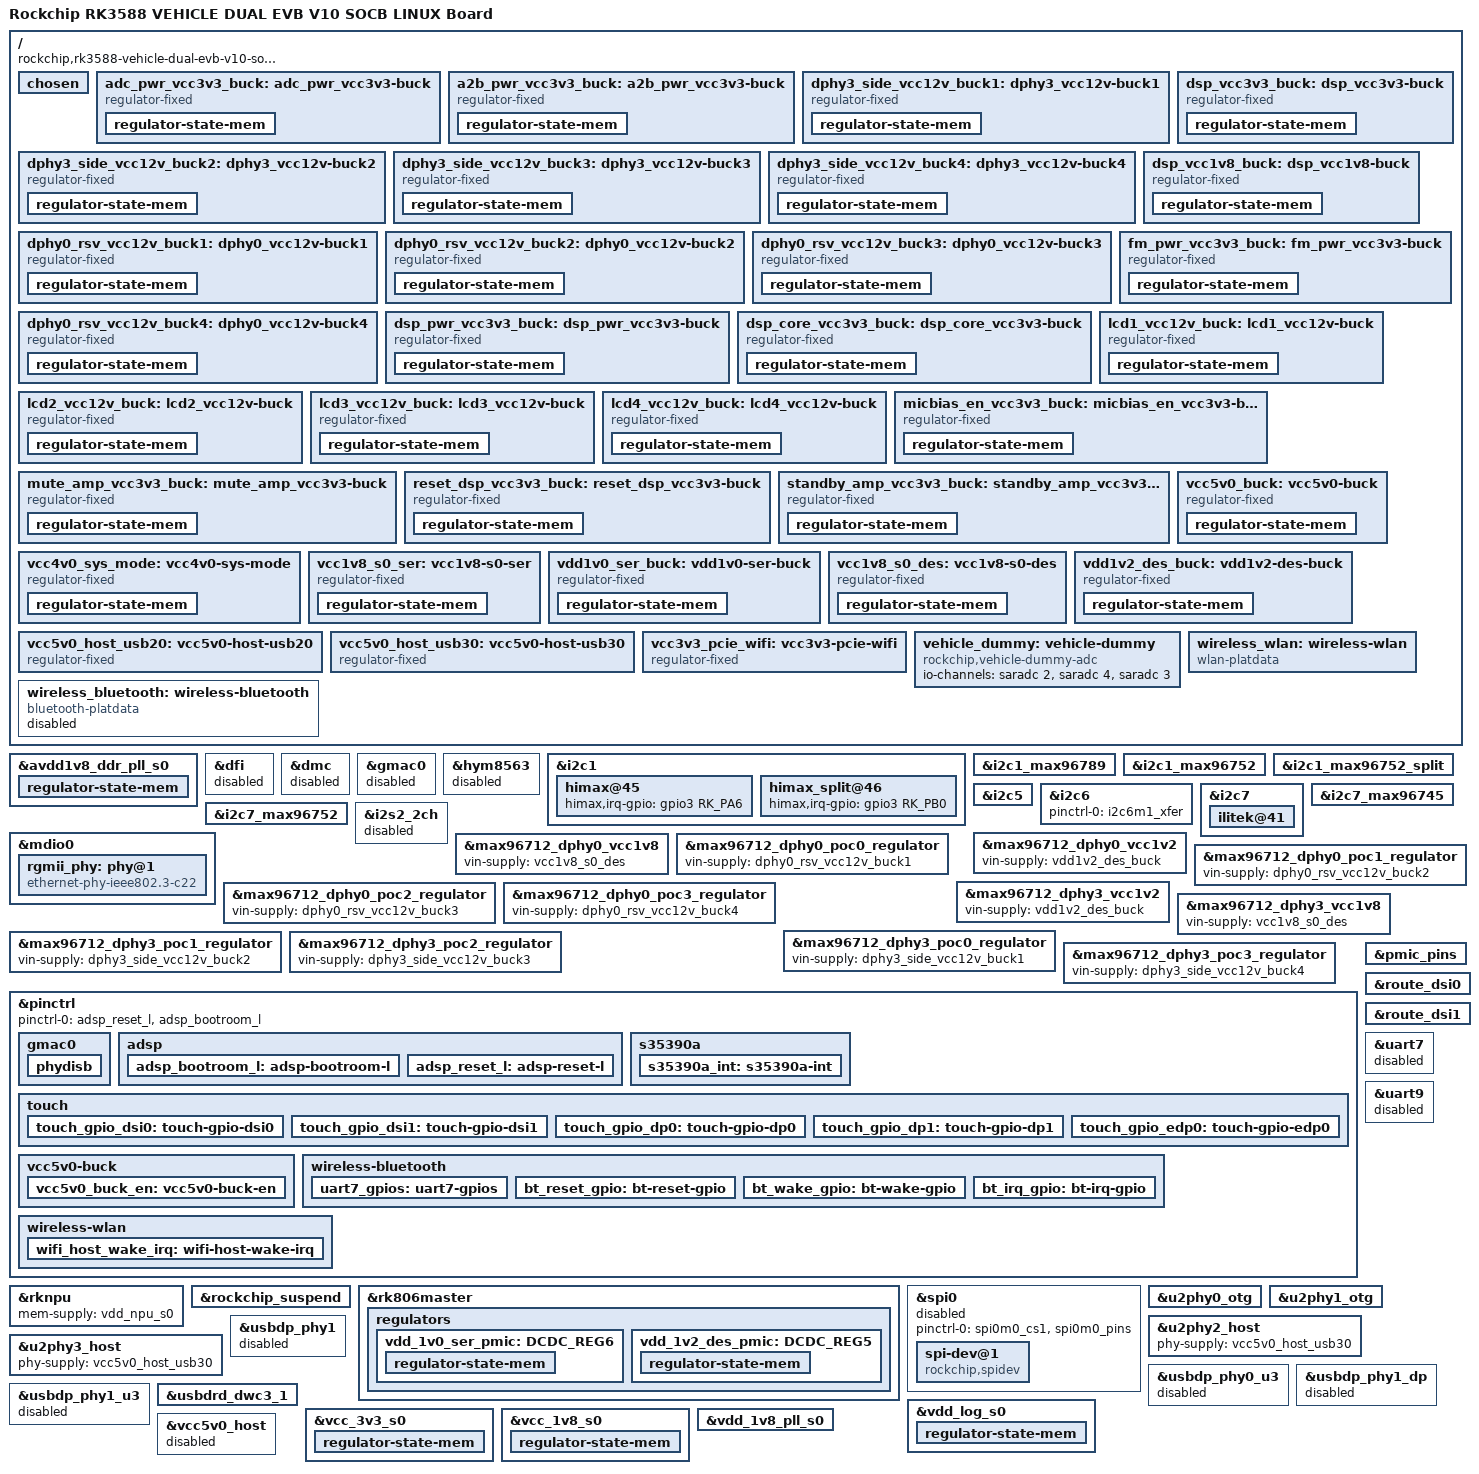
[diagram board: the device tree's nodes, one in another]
// SPDX-License-Identifier: (GPL-2.0+ OR MIT)
/*
 * Copyright (c) 2023 Rockchip Electronics Co., Ltd.
 *
 */

/dts-v1/;

#include "rk3588-vehicle-dual-evb-v10-socb.dtsi"

#include "rk3588-vehicle-dual-evb-v10-socb-mcu-io-expander.dtsi"
#include "rk3588-vehicle-dual-evb-v10-socb-maxim-max96712-dphy0-ox03j10.dtsi"
#include "rk3588-vehicle-dual-evb-v10-socb-maxim-max96712-dphy3-ox03j10.dtsi"
#include "rk3588-vehicle-dual-evb-v10-socb-serdes-mfd-display-maxim.dtsi"
#include "rk3588-linux.dtsi"

/ {
	model = "Rockchip RK3588 VEHICLE DUAL EVB V10 SOCB LINUX Board";
	compatible = "rockchip,rk3588-vehicle-dual-evb-v10-socb-linux", "rockchip,rk3588";

	chosen: chosen {
		bootargs = "earlycon=uart8250,mmio32,0xfeb50000 console=ttyFIQ0 irqchip.gicv3_pseudo_nmi=0 root=PARTUUID=614e0000-0000 rw rootwait rcupdate.rcu_expedited=1 rcu_nocbs=all";
	};

	adc_pwr_vcc3v3_buck: adc_pwr_vcc3v3-buck {
		compatible = "regulator-fixed";
		regulator-name = "adc_pwr_vcc3v3_buck";
		regulator-boot-on;
		regulator-always-on;
		regulator-min-microvolt = <3300000>;
		regulator-max-microvolt = <3300000>;
		enable-active-high;
		gpio = <&gpio_mcu_rockchip_socb MCU_ADC_PWDN_L GPIO_ACTIVE_LOW>;
		vin-supply = <&vcc_3v3_s3>;
		regulator-state-mem {
			regulator-off-in-suspend;
			regulator-suspend-microvolt = <3300000>;
		};
	};

	a2b_pwr_vcc3v3_buck: a2b_pwr_vcc3v3-buck {
		compatible = "regulator-fixed";
		regulator-name = "a2b_pwr_vcc3v3_buck";
		regulator-boot-on;
		regulator-always-on;
		regulator-min-microvolt = <3300000>;
		regulator-max-microvolt = <3300000>;
		enable-active-high;
		gpio = <&gpio_mcu_rockchip_socb MCU_A2B_PWR_EN_H GPIO_ACTIVE_HIGH>;
		vin-supply = <&vcc_3v3_s3>;
		regulator-state-mem {
			regulator-off-in-suspend;
			regulator-suspend-microvolt = <3300000>;
		};
	};

	dphy3_side_vcc12v_buck1: dphy3_vcc12v-buck1 {
		compatible = "regulator-fixed";
		regulator-name = "dphy3_side_vcc12v_buck1";
		regulator-boot-on;
		regulator-min-microvolt = <12000000>;
		regulator-max-microvolt = <12000000>;
		enable-active-high;
		gpio = <&gpio_mcu_rockchip_socb VCC12V_SIDE1 GPIO_ACTIVE_HIGH>;
		startup-delay-us = <2000>;
		off-on-delay-us = <16000>;
		vin-supply = <&vcc12v_dcin>;
		regulator-state-mem {
			regulator-off-in-suspend;
			regulator-suspend-microvolt = <12000000>;
		};
	};

	dphy3_side_vcc12v_buck2: dphy3_vcc12v-buck2 {
		compatible = "regulator-fixed";
		regulator-name = "dphy3_side_vcc12v_buck2";
		regulator-boot-on;
		regulator-min-microvolt = <12000000>;
		regulator-max-microvolt = <12000000>;
		enable-active-high;
		gpio = <&gpio_mcu_rockchip_socb VCC12V_SIDE2 GPIO_ACTIVE_HIGH>;
		startup-delay-us = <2000>;
		off-on-delay-us = <16000>;
		vin-supply = <&vcc12v_dcin>;
		regulator-state-mem {
			regulator-off-in-suspend;
			regulator-suspend-microvolt = <12000000>;
		};
	};

	dphy3_side_vcc12v_buck3: dphy3_vcc12v-buck3 {
		compatible = "regulator-fixed";
		regulator-name = "dphy3_side_vcc12v_buck3";
		regulator-boot-on;
		regulator-min-microvolt = <12000000>;
		regulator-max-microvolt = <12000000>;
		enable-active-high;
		gpio = <&gpio_mcu_rockchip_socb VCC12V_SIDE3 GPIO_ACTIVE_HIGH>;
		startup-delay-us = <2000>;
		off-on-delay-us = <16000>;
		vin-supply = <&vcc12v_dcin>;
		regulator-state-mem {
			regulator-off-in-suspend;
			regulator-suspend-microvolt = <12000000>;
		};
	};

	dphy3_side_vcc12v_buck4: dphy3_vcc12v-buck4 {
		compatible = "regulator-fixed";
		regulator-name = "dphy3_side_vcc12v_buck4";
		regulator-boot-on;
		regulator-min-microvolt = <12000000>;
		regulator-max-microvolt = <12000000>;
		enable-active-high;
		gpio = <&gpio_mcu_rockchip_socb VCC12V_SIDE4 GPIO_ACTIVE_HIGH>;
		startup-delay-us = <2000>;
		off-on-delay-us = <16000>;
		vin-supply = <&vcc12v_dcin>;
		regulator-state-mem {
			regulator-off-in-suspend;
			regulator-suspend-microvolt = <12000000>;
		};
	};

	dphy0_rsv_vcc12v_buck1: dphy0_vcc12v-buck1 {
		compatible = "regulator-fixed";
		regulator-name = "dphy0_rsv_vcc12v_buck1";
		regulator-boot-on;
		regulator-min-microvolt = <12000000>;
		regulator-max-microvolt = <12000000>;
		enable-active-high;
		gpio = <&gpio_mcu_rockchip_socb VCC12V_CAM_RSV1 GPIO_ACTIVE_HIGH>;
		startup-delay-us = <2000>;
		off-on-delay-us = <16000>;
		vin-supply = <&vcc12v_dcin>;
		regulator-state-mem {
			regulator-off-in-suspend;
			regulator-suspend-microvolt = <12000000>;
		};
	};

	dphy0_rsv_vcc12v_buck2: dphy0_vcc12v-buck2 {
		compatible = "regulator-fixed";
		regulator-name = "dphy0_rsv_vcc12v_buck2";
		regulator-boot-on;
		regulator-min-microvolt = <12000000>;
		regulator-max-microvolt = <12000000>;
		enable-active-high;
		gpio = <&gpio_mcu_rockchip_socb VCC12V_CAM_RSV2 GPIO_ACTIVE_HIGH>;
		startup-delay-us = <2000>;
		off-on-delay-us = <16000>;
		vin-supply = <&vcc12v_dcin>;
		regulator-state-mem {
			regulator-off-in-suspend;
			regulator-suspend-microvolt = <12000000>;
		};
	};

	dphy0_rsv_vcc12v_buck3: dphy0_vcc12v-buck3 {
		compatible = "regulator-fixed";
		regulator-name = "dphy0_rsv_vcc12v_buck3";
		regulator-boot-on;
		regulator-min-microvolt = <12000000>;
		regulator-max-microvolt = <12000000>;
		enable-active-high;
		gpio = <&gpio_mcu_rockchip_socb VCC12V_CAM_RSV3 GPIO_ACTIVE_HIGH>;
		startup-delay-us = <2000>;
		off-on-delay-us = <16000>;
		vin-supply = <&vcc12v_dcin>;
		regulator-state-mem {
			regulator-off-in-suspend;
			regulator-suspend-microvolt = <12000000>;
		};
	};

	dphy0_rsv_vcc12v_buck4: dphy0_vcc12v-buck4 {
		compatible = "regulator-fixed";
		regulator-name = "dphy0_rsv_vcc12v_buck4";
		regulator-boot-on;
		regulator-min-microvolt = <12000000>;
		regulator-max-microvolt = <12000000>;
		enable-active-high;
		gpio = <&gpio_mcu_rockchip_socb VCC12V_CAM_RSV4 GPIO_ACTIVE_HIGH>;
		startup-delay-us = <2000>;
		off-on-delay-us = <16000>;
		vin-supply = <&vcc12v_dcin>;
		regulator-state-mem {
			regulator-off-in-suspend;
			regulator-suspend-microvolt = <12000000>;
		};
	};

	dsp_vcc3v3_buck: dsp_vcc3v3-buck {
		compatible = "regulator-fixed";
		regulator-name = "dsp_vcc3v3_buck";
		regulator-boot-on;
		regulator-always-on;
		regulator-min-microvolt = <3300000>;
		regulator-max-microvolt = <3300000>;
		enable-active-high;
		gpio = <&gpio_mcu_rockchip_socb MCU_DSP_3V3_EN_H GPIO_ACTIVE_HIGH>;
		vin-supply = <&vcc_3v3_s3>;
		regulator-state-mem {
			regulator-off-in-suspend;
			regulator-suspend-microvolt = <3300000>;
		};
	};

	dsp_vcc1v8_buck: dsp_vcc1v8-buck {
		compatible = "regulator-fixed";
		regulator-name = "dsp_vcc1v8_buck";
		regulator-boot-on;
		regulator-always-on;
		regulator-min-microvolt = <1800000>;
		regulator-max-microvolt = <1800000>;
		enable-active-high;
		gpio = <&gpio_mcu_rockchip_socb MCU_DSP_1V8_EN_H GPIO_ACTIVE_HIGH>;
		vin-supply = <&vcc_1v8_s0>;
		regulator-state-mem {
			regulator-off-in-suspend;
			regulator-suspend-microvolt = <1800000>;
		};
	};

	dsp_pwr_vcc3v3_buck: dsp_pwr_vcc3v3-buck {
		compatible = "regulator-fixed";
		regulator-name = "dsp_pwr_vcc3v3_buck";
		regulator-boot-on;
		regulator-always-on;
		regulator-min-microvolt = <3300000>;
		regulator-max-microvolt = <3300000>;
		enable-active-high;
		gpio = <&gpio_mcu_rockchip_socb MCU_DSP0_PWREN_H GPIO_ACTIVE_HIGH>;
		vin-supply = <&vcc_3v3_s3>;
		regulator-state-mem {
			regulator-off-in-suspend;
			regulator-suspend-microvolt = <3300000>;
		};
	};

	dsp_core_vcc3v3_buck: dsp_core_vcc3v3-buck {
		compatible = "regulator-fixed";
		regulator-name = "dsp_core_vcc3v3_buck";
		regulator-boot-on;
		regulator-always-on;
		regulator-min-microvolt = <3300000>;
		regulator-max-microvolt = <3300000>;
		enable-active-high;
		gpio = <&gpio_mcu_rockchip_socb MCU_DSPCORE_PWREN_H GPIO_ACTIVE_HIGH>;
		vin-supply = <&vcc_3v3_s3>;
		regulator-state-mem {
			regulator-off-in-suspend;
			regulator-suspend-microvolt = <3300000>;
		};
	};

	fm_pwr_vcc3v3_buck: fm_pwr_vcc3v3-buck {
		compatible = "regulator-fixed";
		regulator-name = "fm_pwr_vcc3v3_buck";
		regulator-boot-on;
		regulator-always-on;
		regulator-min-microvolt = <3300000>;
		regulator-max-microvolt = <3300000>;
		enable-active-high;
		gpio = <&gpio_mcu_rockchip_socb MCU_FM_PWR_EN_H GPIO_ACTIVE_HIGH>;
		vin-supply = <&vcc_3v3_s3>;
		regulator-state-mem {
			regulator-off-in-suspend;
			regulator-suspend-microvolt = <3300000>;
		};
	};

	lcd1_vcc12v_buck: lcd1_vcc12v-buck {
		compatible = "regulator-fixed";
		regulator-name = "lcd1_vcc12v_buck";
		regulator-boot-on;
		regulator-always-on;
		regulator-min-microvolt = <12000000>;
		regulator-max-microvolt = <12000000>;
		enable-active-high;
		gpio = <&gpio_mcu_rockchip_socb MCU_LCD_Cluster_12V_EN_B GPIO_ACTIVE_HIGH>;
		vin-supply = <&vcc12v_dcin>;
		regulator-state-mem {
			regulator-off-in-suspend;
			regulator-suspend-microvolt = <12000000>;
		};
	};

	lcd2_vcc12v_buck: lcd2_vcc12v-buck {
		compatible = "regulator-fixed";
		regulator-name = "lcd2_vcc12v_buck";
		regulator-boot-on;
		regulator-always-on;
		regulator-min-microvolt = <12000000>;
		regulator-max-microvolt = <12000000>;
		enable-active-high;
		gpio = <&gpio_mcu_rockchip_socb MCU_LCD_HUD_12V_EN_B GPIO_ACTIVE_HIGH>;
		vin-supply = <&vcc12v_dcin>;
		regulator-state-mem {
			regulator-off-in-suspend;
			regulator-suspend-microvolt = <12000000>;
		};
	};

	lcd3_vcc12v_buck: lcd3_vcc12v-buck {
		compatible = "regulator-fixed";
		regulator-name = "lcd3_vcc12v_buck";
		regulator-boot-on;
		regulator-always-on;
		regulator-min-microvolt = <12000000>;
		regulator-max-microvolt = <12000000>;
		enable-active-high;
		gpio = <&gpio_mcu_rockchip_socb MCU_LCD_PAS_12V_EN_B GPIO_ACTIVE_HIGH>;
		vin-supply = <&vcc12v_dcin>;
		regulator-state-mem {
			regulator-off-in-suspend;
			regulator-suspend-microvolt = <12000000>;
		};
	};

	lcd4_vcc12v_buck: lcd4_vcc12v-buck {
		compatible = "regulator-fixed";
		regulator-name = "lcd4_vcc12v_buck";
		regulator-boot-on;
		regulator-always-on;
		regulator-min-microvolt = <12000000>;
		regulator-max-microvolt = <12000000>;
		enable-active-high;
		gpio = <&gpio_mcu_rockchip_socb MCU_eDP_12V_EN_B GPIO_ACTIVE_HIGH>;
		vin-supply = <&vcc12v_dcin>;
		regulator-state-mem {
			regulator-off-in-suspend;
			regulator-suspend-microvolt = <12000000>;
		};
	};

	micbias_en_vcc3v3_buck: micbias_en_vcc3v3-buck {
		compatible = "regulator-fixed";
		regulator-name = "micbias_en_vcc3v3_buck";
		regulator-boot-on;
		regulator-always-on;
		regulator-min-microvolt = <3300000>;
		regulator-max-microvolt = <3300000>;
		enable-active-high;
		gpio = <&gpio_mcu_rockchip_socb MCU_MICBIAS_EN GPIO_ACTIVE_HIGH>;
		vin-supply = <&vcc_3v3_s3>;
		regulator-state-mem {
			regulator-off-in-suspend;
			regulator-suspend-microvolt = <3300000>;
		};
	};

	mute_amp_vcc3v3_buck: mute_amp_vcc3v3-buck {
		compatible = "regulator-fixed";
		regulator-name = "mute_amp_vcc3v3_buck";
		regulator-boot-on;
		regulator-always-on;
		regulator-min-microvolt = <3300000>;
		regulator-max-microvolt = <3300000>;
		enable-active-high;
		gpio = <&gpio_mcu_rockchip_socb MCU_MUTE_AMP_L GPIO_ACTIVE_HIGH>;
		vin-supply = <&vcc_3v3_s3>;
		regulator-state-mem {
			regulator-off-in-suspend;
			regulator-suspend-microvolt = <3300000>;
		};
	};

	reset_dsp_vcc3v3_buck: reset_dsp_vcc3v3-buck {
		compatible = "regulator-fixed";
		regulator-name = "reset_dsp_vcc3v3_buck";
		regulator-boot-on;
		regulator-always-on;
		regulator-min-microvolt = <3300000>;
		regulator-max-microvolt = <3300000>;
		enable-active-high;
		gpio = <&gpio_mcu_rockchip_socb MCU_RESET_DSP GPIO_ACTIVE_HIGH>;
		vin-supply = <&vcc_3v3_s3>;
		regulator-state-mem {
			regulator-off-in-suspend;
			regulator-suspend-microvolt = <3300000>;
		};
	};

	standby_amp_vcc3v3_buck: standby_amp_vcc3v3-buck {
		compatible = "regulator-fixed";
		regulator-name = "standby_amp_vcc3v3_buck";
		regulator-boot-on;
		regulator-always-on;
		regulator-min-microvolt = <3300000>;
		regulator-max-microvolt = <3300000>;
		enable-active-high;
		gpio = <&gpio_mcu_rockchip_socb MCU_STANDBY_AMP_L GPIO_ACTIVE_LOW>;
		vin-supply = <&vcc_3v3_s3>;
		regulator-state-mem {
			regulator-off-in-suspend;
			regulator-suspend-microvolt = <3300000>;
		};
	};

	vcc5v0_buck: vcc5v0-buck {
		compatible = "regulator-fixed";
		regulator-name = "vcc5v0_buck";
		regulator-boot-on;
		regulator-always-on;
		regulator-min-microvolt = <5000000>;
		regulator-max-microvolt = <5000000>;
		enable-active-high;
		gpio = <&gpio0 RK_PC2 GPIO_ACTIVE_HIGH>;
		vin-supply = <&vcc12v_dcin>;
		pinctrl-names = "default";
		pinctrl-0 = <&vcc5v0_buck_en>;
		startup-delay-us = <2500>;
		off-on-delay-us = <1500>;
		regulator-state-mem {
			regulator-on-in-suspend;
			regulator-suspend-microvolt = <5000000>;
		};
	};

	vcc4v0_sys_mode: vcc4v0-sys-mode {
		compatible = "regulator-fixed";
		regulator-name = "vcc4v0_sys_mode";
		regulator-boot-on;
		regulator-always-on;
		regulator-min-microvolt = <4000000>;
		regulator-max-microvolt = <4000000>;
		enable-active-high;
		gpio = <&gpio_mcu_rockchip_socb MCU_CTRL_SOCB_VSYS GPIO_ACTIVE_LOW>;
		vin-supply = <&vcc12v_dcin>;
		regulator-state-mem {
			regulator-off-in-suspend;
			regulator-suspend-microvolt = <4000000>;
		};
	};

	vcc1v8_s0_ser: vcc1v8-s0-ser {
		compatible = "regulator-fixed";
		regulator-name = "vcc1v8_s0_ser";
		regulator-boot-on;
		regulator-always-on;
		regulator-min-microvolt = <1800000>;
		regulator-max-microvolt = <1800000>;
		enable-active-high;
		gpio = <&gpio0 RK_PC5 GPIO_ACTIVE_HIGH>;
		vin-supply = <&vcc_1v8_s0>;
		regulator-state-mem {
			regulator-off-in-suspend;
			regulator-suspend-microvolt = <1800000>;
		};
	};

	vdd1v0_ser_buck: vdd1v0-ser-buck {
		compatible = "regulator-fixed";
		regulator-name = "vdd1v0_ser_buck";
		regulator-boot-on;
		regulator-always-on;
		regulator-min-microvolt = <1000000>;
		regulator-max-microvolt = <1000000>;
		enable-active-high;
		vin-supply = <&vdd_1v0_ser_pmic>;
		regulator-state-mem {
			regulator-off-in-suspend;
			regulator-suspend-microvolt = <1000000>;
		};
	};

	vcc1v8_s0_des: vcc1v8-s0-des {
		compatible = "regulator-fixed";
		regulator-name = "vcc1v8_s0_des";
		regulator-boot-on;
		regulator-always-on;
		regulator-min-microvolt = <1800000>;
		regulator-max-microvolt = <1800000>;
		enable-active-high;
		gpio = <&gpio0 RK_PD3 GPIO_ACTIVE_HIGH>;
		vin-supply = <&vcc_1v8_s0>;
		regulator-state-mem {
			regulator-off-in-suspend;
			regulator-suspend-microvolt = <1800000>;
		};
	};

	vdd1v2_des_buck: vdd1v2-des-buck {
		compatible = "regulator-fixed";
		regulator-name = "vdd1v2_des_buck";
		regulator-boot-on;
		regulator-always-on;
		regulator-min-microvolt = <1200000>;
		regulator-max-microvolt = <1200000>;
		enable-active-high;
		vin-supply = <&vdd_1v2_des_pmic>;
		regulator-state-mem {
			regulator-off-in-suspend;
			regulator-suspend-microvolt = <1200000>;
		};
	};

	vcc5v0_host_usb20: vcc5v0-host-usb20 {
		compatible = "regulator-fixed";
		regulator-name = "vcc5v0_host_usb20";
		regulator-boot-on;
		regulator-always-on;
		regulator-min-microvolt = <5000000>;
		regulator-max-microvolt = <5000000>;
		//enable-active-high;
		gpio = <&gpio_mcu_rockchip_socb MCU_USB2_HOST_PWREN_H_B GPIO_ACTIVE_HIGH>;
		startup-delay-us = <2000>;
		off-on-delay-us = <16000>;
		vin-supply = <&vcc5v0_buck>;
	};

	vcc5v0_host_usb30: vcc5v0-host-usb30 {
		compatible = "regulator-fixed";
		regulator-name = "vcc5v0_host_usb30";
		regulator-boot-on;
		regulator-always-on;
		regulator-min-microvolt = <5000000>;
		regulator-max-microvolt = <5000000>;
		enable-active-high;
		gpio = <&gpio_mcu_rockchip_socb MCU_USB3_HOST_PWREN_H_B GPIO_ACTIVE_HIGH>;
		startup-delay-us = <2000>;
		off-on-delay-us = <16000>;
		vin-supply = <&vcc5v0_buck>;
	};

	vcc3v3_pcie_wifi: vcc3v3-pcie-wifi {
		compatible = "regulator-fixed";
		regulator-name = "vcc3v3_pcie_wifi";
		regulator-always-on;
		regulator-min-microvolt = <3300000>;
		regulator-max-microvolt = <3300000>;
		enable-active-high;
		gpios = <&gpio0 RK_PB2 GPIO_ACTIVE_HIGH>;
		startup-delay-us = <5000>;
		vin-supply = <&vcc_3v3_s3>;
	};

	vehicle_dummy: vehicle-dummy {
		status = "okay";
		compatible = "rockchip,vehicle-dummy-adc";
		io-channels = <&saradc 2>, <&saradc 4>, <&saradc 3>;
		io-channel-names = "gear", "turn_left", "turn_right";
	};

	wireless_bluetooth: wireless-bluetooth {
		compatible = "bluetooth-platdata";
		bt_port = "/dev/ttyS7";
		clocks = <&hym8563>;
		clock-names = "ext_clock";
		uart_rts_gpios = <&gpio3 RK_PC2 GPIO_ACTIVE_LOW>;
		pinctrl-names = "default", "rts_gpio";
		pinctrl-0 = <&uart7m1_rtsn>, <&bt_reset_gpio>, <&bt_wake_gpio>, <&bt_irq_gpio>;
		pinctrl-1 = <&uart7_gpios>;
		BT,reset_gpio    = <&gpio0 RK_PD6 GPIO_ACTIVE_HIGH>;
		BT,wake_gpio     = <&gpio3 RK_PB7 GPIO_ACTIVE_HIGH>;
		BT,wake_host_irq = <&gpio0 RK_PA4 GPIO_ACTIVE_HIGH>;
		status = "disabled";
	};

	wireless_wlan: wireless-wlan {
		compatible = "wlan-platdata";
		wifi_chip_type = "ap6398s";
		pinctrl-names = "default";
		pinctrl-0 = <&wifi_host_wake_irq>;
		WIFI,host_wake_irq = <&gpio0 RK_PA0 GPIO_ACTIVE_HIGH>;
		WIFI,poweren_gpio = <&gpio0 RK_PB2 GPIO_ACTIVE_HIGH>;
		status = "okay";
	};
};

&avdd1v8_ddr_pll_s0 {
	regulator-state-mem {
		regulator-on-in-suspend;
		regulator-suspend-microvolt = <1800000>;
	};
};

&dfi {
	status = "disabled";
};

&dmc {
	status = "disabled";
};

&gmac0 {
	/* Use rgmii-rxid mode to disable rx delay inside Soc */
	phy-mode = "rgmii-rxid";
	clock_in_out = "output";
	snps,reset-gpio = <&gpio2 RK_PC5 GPIO_ACTIVE_LOW>;
	snps,reset-active-low;
	/* Reset time is 20ms, 100ms for rtl8211f */
	snps,reset-delays-us = <0 20000 100000>;
	pinctrl-names = "default";
	pinctrl-0 = <&gmac0_miim
		     &gmac0_tx_bus2
		     &gmac0_rx_bus2
		     &gmac0_rgmii_clk
		     &gmac0_rgmii_bus>;
	tx_delay = <0x20>;
	phy-handle = <&rgmii_phy>;
	status = "disabled";
};

&hym8563 {
	status = "disabled";
};

&i2c1 {
	himax@45 {
		himax,irq-gpio = <&gpio3 RK_PA6 IRQ_TYPE_EDGE_FALLING>;
	};

	himax_split@46 {
		himax,irq-gpio = <&gpio3 RK_PB0 IRQ_TYPE_EDGE_FALLING>;
	};
};

&i2c1_max96789 {
	lock-gpios = <&gpio1 RK_PD4 GPIO_ACTIVE_HIGH>;
	enable-gpios = <&gpio1 RK_PC1 GPIO_ACTIVE_HIGH>;
	route-enable;
};

&i2c1_max96752 {
	use-reg-check-work;
	vpower-supply = <&lcd1_vcc12v_buck>;
};

&i2c1_max96752_split {
	use-reg-check-work;
	vpower-supply = <&lcd2_vcc12v_buck>;
};

&i2c5 {
	status = "okay";
	clock-frequency = <400000>;
	pinctrl-names = "default";
	pinctrl-0 = <&i2c5m0_xfer>;
};

&i2c6 {
	pinctrl-names = "default";
	pinctrl-0 = <&i2c6m1_xfer>;
};

&i2c7 {
	ilitek@41 {
		interrupt-parent = <&gpio3>;
		interrupts = <RK_PC4 IRQ_TYPE_LEVEL_LOW>;
	};
};

&i2c7_max96745 {
	lock-gpios = <&gpio2 RK_PC4 GPIO_ACTIVE_HIGH>;
	enable-gpios = <&gpio2 RK_PB5 GPIO_ACTIVE_HIGH>;
};

&i2c7_max96752 {
	use-reg-check-work;
	vpower-supply = <&lcd3_vcc12v_buck>;
};

&i2c7 {
	status = "okay";
	clock-frequency = <400000>;
	pinctrl-names = "default";
	pinctrl-0 = <&i2c7m0_xfer>;
};

&i2s2_2ch {
	status = "disabled";
};

&mdio0 {
	rgmii_phy: phy@1 {
		compatible = "ethernet-phy-ieee802.3-c22";
		reg = <0x1>;
		motorcomm,vddio = "1v8";
	};
};

&max96712_dphy0_vcc1v2 {
	vin-supply = <&vdd1v2_des_buck>;
};

&max96712_dphy0_vcc1v8 {
	vin-supply = <&vcc1v8_s0_des>;
};

&max96712_dphy0_poc0_regulator {
	vin-supply = <&dphy0_rsv_vcc12v_buck1>;
};

&max96712_dphy0_poc1_regulator {
	vin-supply = <&dphy0_rsv_vcc12v_buck2>;
};

&max96712_dphy0_poc2_regulator {
	vin-supply = <&dphy0_rsv_vcc12v_buck3>;
};

&max96712_dphy0_poc3_regulator {
	vin-supply = <&dphy0_rsv_vcc12v_buck4>;
};

&max96712_dphy3_vcc1v2 {
	vin-supply = <&vdd1v2_des_buck>;
};

&max96712_dphy3_vcc1v8 {
	vin-supply = <&vcc1v8_s0_des>;
};

&max96712_dphy3_poc0_regulator {
	vin-supply = <&dphy3_side_vcc12v_buck1>;
};

&max96712_dphy3_poc1_regulator {
	vin-supply = <&dphy3_side_vcc12v_buck2>;
};

&max96712_dphy3_poc2_regulator {
	vin-supply = <&dphy3_side_vcc12v_buck3>;
};

&max96712_dphy3_poc3_regulator {
	vin-supply = <&dphy3_side_vcc12v_buck4>;
};

&pinctrl {
	pinctrl-names = "init";
	pinctrl-0 = <&adsp_reset_l
			&adsp_bootroom_l>;

	gmac0 {
		phydisb: phydisb {
			rockchip,pins = <4 RK_PC6 RK_FUNC_GPIO &pcfg_output_high>;
		};
	};

	adsp {
		adsp_bootroom_l: adsp-bootroom-l {
			rockchip,pins = <2 RK_PB5 RK_FUNC_GPIO &pcfg_output_low_pull_down>;
		};

		adsp_reset_l: adsp-reset-l {
			rockchip,pins = <4 RK_PA7 RK_FUNC_GPIO &pcfg_output_low_pull_down>;
		};
	};

	s35390a {
		s35390a_int: s35390a-int {
			rockchip,pins = <0 RK_PC3 RK_FUNC_GPIO &pcfg_pull_up>;
		};
	};

	touch {
		//dsi0-i2c2
		touch_gpio_dsi0: touch-gpio-dsi0 {
			rockchip,pins =
				<3 RK_PA6 RK_FUNC_GPIO &pcfg_pull_up>;
		};
		//dsi1-i2c2
		touch_gpio_dsi1: touch-gpio-dsi1 {
			rockchip,pins =
				<3 RK_PB0 RK_FUNC_GPIO &pcfg_pull_up>;
		};
		//dp0-i2c7
		touch_gpio_dp0: touch-gpio-dp0 {
			rockchip,pins =
				<3 RK_PC4 RK_FUNC_GPIO &pcfg_pull_up>;
		};
		//dp1-i2c4
		touch_gpio_dp1: touch-gpio-dp1 {
			rockchip,pins =
				<2 RK_PB4 RK_FUNC_GPIO &pcfg_pull_up>;
		};
		//edp0-i2c5
		touch_gpio_edp0: touch-gpio-edp0 {
			rockchip,pins =
				<3 RK_PD4 RK_FUNC_GPIO &pcfg_pull_up>;
		};
	};

	vcc5v0-buck {
		vcc5v0_buck_en: vcc5v0-buck-en {
			rockchip,pins = <0 RK_PC2 RK_FUNC_GPIO &pcfg_pull_none>;
		};
	};

	wireless-bluetooth {
		uart7_gpios: uart7-gpios {
			rockchip,pins = <3 RK_PC2 RK_FUNC_GPIO &pcfg_pull_none>;
		};

		bt_reset_gpio: bt-reset-gpio {
			rockchip,pins = <0 RK_PD6 RK_FUNC_GPIO &pcfg_pull_none>;
		};

		bt_wake_gpio: bt-wake-gpio {
			rockchip,pins = <3 RK_PB7 RK_FUNC_GPIO &pcfg_pull_none>;
		};

		bt_irq_gpio: bt-irq-gpio {
			rockchip,pins = <0 RK_PA4 RK_FUNC_GPIO &pcfg_pull_none>;
		};
	};

	wireless-wlan {
		wifi_host_wake_irq: wifi-host-wake-irq {
			rockchip,pins = <0 RK_PA0 RK_FUNC_GPIO &pcfg_pull_down>;
		};
	};
};

&pmic_pins {
	rockchip,pins =
		/* pmic_int_l */
		<0 RK_PA7 0 &pcfg_pull_up>,
		/* pmic_sleep1 */
		<0 RK_PA2 1 &pcfg_pull_none>,
		/* pmic_sleep2 */
		<0 RK_PA3 1 &pcfg_pull_none>,
		/* pmic_sleep3 */
		<0 RK_PC1 1 &pcfg_pull_none>;
};

&rknpu {
	mem-supply = <&vdd_npu_s0>;
	status = "okay";
};

&rockchip_suspend {
	rockchip,sleep-mode-config = <
		(0
		| RKPM_SLP_ARMOFF_DDRPD
		| RKPM_SLP_PMU_PMUALIVE_32K
		| RKPM_SLP_PMU_DIS_OSC
		| RKPM_SLP_32K_EXT
		)
	>;
	rockchip,wakeup-config = <
		(0
		| RKPM_CPU0_WKUP_EN
		| RKPM_GPIO_WKUP_EN
		)
	>;
	status = "okay";
};

&route_dsi0 {
	status = "okay";
};

&route_dsi1 {
	status = "okay";
};

&rk806master {
	regulators {
		/delete-node/ vdd_npu_mem_s0;
		/delete-node/ vdd_gpu_mem_s0;

		vdd_1v0_ser_pmic: DCDC_REG6 {
			regulator-always-on;
			regulator-boot-on;
			regulator-min-microvolt = <1000000>;
			regulator-max-microvolt = <1000000>;
			regulator-ramp-delay = <12500>;
			regulator-name = "vdd_1v0_ser_pmic";
			regulator-state-mem {
				regulator-off-in-suspend;
				regulator-suspend-microvolt = <1000000>;
			};
		};

		vdd_1v2_des_pmic: DCDC_REG5 {
			regulator-always-on;
			regulator-boot-on;
			regulator-min-microvolt = <1200000>;
			regulator-max-microvolt = <1200000>;
			regulator-ramp-delay = <12500>;
			regulator-name = "vdd_1v2_des_pmic";
			regulator-state-mem {
				regulator-off-in-suspend;
				regulator-suspend-microvolt = <1200000>;
			};
		};
	};
};

&spi0 {
	status = "disabled";
	pinctrl-names = "default";
	pinctrl-0 = <&spi0m0_cs1 &spi0m0_pins>;
	spi-dev@1 {
		compatible = "rockchip,spidev";
		reg = <0x1>;
		spi-max-frequency = <50000000>;
		spi-lsb-first;
	};
};

&uart7 {
	status = "disabled";
};

&uart9 {
	status = "disabled";
};

&u2phy0_otg {
	//phy-supply = <&vcc5v0_host_usb20>;
	status = "okay";
};

&u2phy1_otg {
	phy-supply = <&vcc5v0_host_usb30>;
	rockchip,sel-pipe-phystatus;
};

&u2phy2_host {
	phy-supply = <&vcc5v0_host_usb30>;
};

&u2phy3_host {
	phy-supply = <&vcc5v0_host_usb30>;
};

&usbdp_phy0_u3 {
	status = "disabled";
};

&usbdp_phy1 {
	status = "disabled";
};

&usbdp_phy1_dp {
	status = "disabled";
};

&usbdp_phy1_u3 {
	status = "disabled";
};

&usbdrd_dwc3_1 {
	dr_mode = "host";
	phys = <&u2phy1_otg>;
	phy-names = "usb2-phy";
	maximum-speed = "high-speed";
	extcon = <&u2phy1>;
	snps,dis_u2_susphy_quirk;
	snps,usb2-lpm-disable;
	status = "okay";
};

&vdd_log_s0 {
	regulator-state-mem {
		regulator-on-in-suspend;
		regulator-suspend-microvolt = <800000>;
	};
};

&vcc_3v3_s0 {
	regulator-state-mem {
		regulator-on-in-suspend;
		regulator-suspend-microvolt = <3300000>;
	};
};

&vcc_1v8_s0 {
	regulator-state-mem {
		regulator-on-in-suspend;
		regulator-suspend-microvolt = <1800000>;
	};
};

&vdd_1v8_pll_s0 {
		regulator-on-in-suspend;
		regulator-suspend-microvolt = <1800000>;
};

&vcc5v0_host {
	status = "disabled";
};
